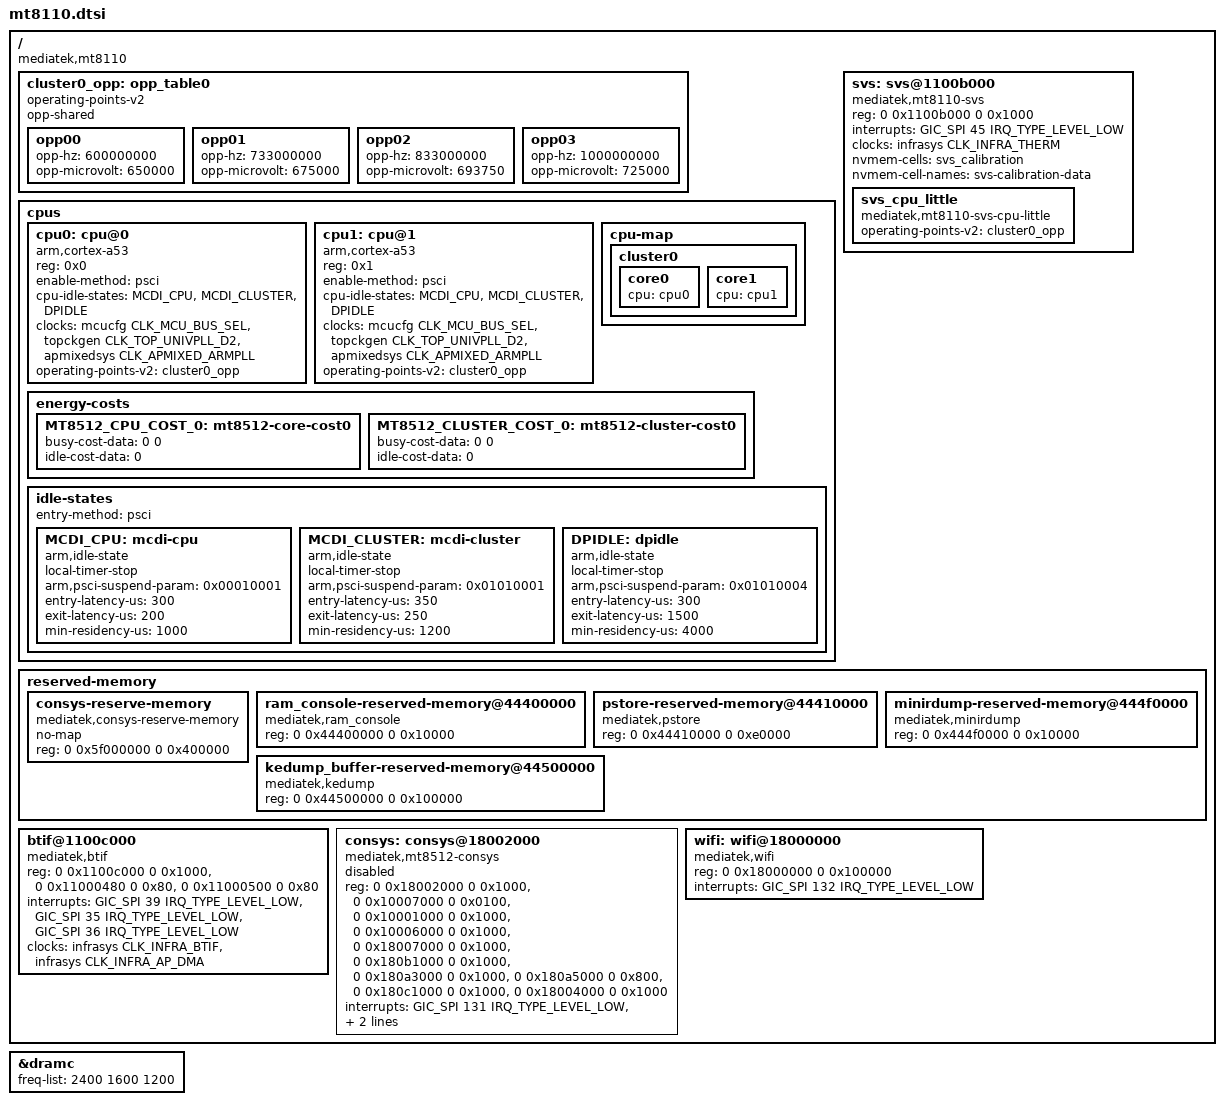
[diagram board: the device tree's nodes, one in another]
/*
 * Copyright (c) 2019 MediaTek Inc.
 *
 * SPDX-License-Identifier: (GPL-2.0 OR MIT)
 */

#include "mt8512.dtsi"

/ {
	compatible = "mediatek,mt8110";
	cluster0_opp: opp_table0 {
		compatible = "operating-points-v2";
		opp-shared;
		opp00 {
			opp-hz = /bits/ 64 <600000000>;
			opp-microvolt = <650000>;
		};
		opp01 {
			opp-hz = /bits/ 64 <733000000>;
			opp-microvolt = <675000>;
		};
		opp02 {
			opp-hz = /bits/ 64 <833000000>;
			opp-microvolt = <693750>;
		};
		opp03 {
			opp-hz = /bits/ 64 <1000000000>;
			opp-microvolt = <725000>;
		};
	};

	cpus {
		#address-cells = <1>;
		#size-cells = <0>;

		cpu0: cpu@0 {
			device_type = "cpu";
			compatible = "arm,cortex-a53";
			reg = <0x0>;
			enable-method = "psci";
			cpu-idle-states = <&MCDI_CPU &MCDI_CLUSTER &DPIDLE>;
			clocks = <&mcucfg CLK_MCU_BUS_SEL>,
				<&topckgen CLK_TOP_UNIVPLL_D2>,
				<&apmixedsys CLK_APMIXED_ARMPLL>;
			clock-names = "cpu", "intermediate", "armpll";
			operating-points-v2 = <&cluster0_opp>;
		};

		cpu1: cpu@1 {
			device_type = "cpu";
			compatible = "arm,cortex-a53";
			reg = <0x1>;
			enable-method = "psci";
			cpu-idle-states = <&MCDI_CPU &MCDI_CLUSTER &DPIDLE>;
			clocks = <&mcucfg CLK_MCU_BUS_SEL>,
				<&topckgen CLK_TOP_UNIVPLL_D2>,
				<&apmixedsys CLK_APMIXED_ARMPLL>;
			clock-names = "cpu", "intermediate", "armpll";
			operating-points-v2 = <&cluster0_opp>;
		};

		cpu-map {
			cluster0 {
				core0 {
					cpu = <&cpu0>;
				};
				core1 {
					cpu = <&cpu1>;
				};
			};
		};

		energy-costs {
			MT8512_CPU_COST_0: mt8512-core-cost0 {
				busy-cost-data = <0 0>;
				idle-cost-data = <0>;
			};
			MT8512_CLUSTER_COST_0: mt8512-cluster-cost0 {
				busy-cost-data = <0 0>;
				idle-cost-data = <0>;
			};
		};

		idle-states {
			entry-method = "psci";

			MCDI_CPU: mcdi-cpu {
				compatible = "arm,idle-state";
				local-timer-stop;
				arm,psci-suspend-param = <0x00010001>;
				entry-latency-us = <300>;
				exit-latency-us = <200>;
				min-residency-us = <1000>;
			};

			MCDI_CLUSTER: mcdi-cluster {
				compatible = "arm,idle-state";
				local-timer-stop;
				arm,psci-suspend-param = <0x01010001>;
				entry-latency-us = <350>;
				exit-latency-us = <250>;
				min-residency-us = <1200>;
			};

			DPIDLE: dpidle {
				compatible = "arm,idle-state";
				local-timer-stop;
				arm,psci-suspend-param = <0x01010004>;
				entry-latency-us = <300>;
				exit-latency-us = <1500>;
				min-residency-us = <4000>;
			};
		};
	};

	svs: svs@1100b000 {
		compatible = "mediatek,mt8110-svs";
		reg = <0 0x1100b000 0 0x1000>;
		interrupts = <GIC_SPI 45 IRQ_TYPE_LEVEL_LOW>;
		clocks = <&infrasys CLK_INFRA_THERM>;
		clock-names = "main_clk";
		nvmem-cells = <&svs_calibration>;
		nvmem-cell-names = "svs-calibration-data";

		svs_cpu_little: svs_cpu_little {
			compatible = "mediatek,mt8110-svs-cpu-little";
			operating-points-v2 = <&cluster0_opp>;
		};
	};

	reserved-memory {
		#address-cells = <2>;
		#size-cells = <2>;
		ranges;

		consys-reserve-memory {
			compatible = "mediatek,consys-reserve-memory";
			no-map;
			reg = <0 0x5f000000 0 0x400000>;
		};

		ram_console-reserved-memory@44400000{
			compatible = "mediatek,ram_console";
			reg = <0 0x44400000 0 0x10000>;
		};

		pstore-reserved-memory@44410000 {
			compatible = "mediatek,pstore";
			reg = <0 0x44410000 0 0xe0000>;
		};

		minirdump-reserved-memory@444f0000{
			compatible = "mediatek,minirdump";
			reg = <0 0x444f0000 0 0x10000>;
		};

		kedump_buffer-reserved-memory@44500000{
			compatible = "mediatek,kedump";
			reg = <0 0x44500000 0 0x100000>;
		};
	};

	btif@1100c000 {
		compatible = "mediatek,btif";
			/*btif base*/
		reg = <0 0x1100c000 0 0x1000>,
			/*btif tx dma base*/
			<0 0x11000480 0 0x80>,
			/*btif rx dma base*/
			<0 0x11000500 0 0x80>;
			/*btif irq, IRQS_Sync ID, btif_irq_b*/
		interrupts = <GIC_SPI 39 IRQ_TYPE_LEVEL_LOW>,
			/*btif tx dma irq*/
			<GIC_SPI 35 IRQ_TYPE_LEVEL_LOW>,
			/*btif rx dma irq*/
			<GIC_SPI 36 IRQ_TYPE_LEVEL_LOW>;
		clocks = <&infrasys CLK_INFRA_BTIF>,
			/*btif clock*/
			<&infrasys CLK_INFRA_AP_DMA>;
			/*ap dma clock*/
		clock-names = "btifc","apdmac";
	};

	consys: consys@18002000 {
		compatible = "mediatek,mt8512-consys";
		#address-cells = <2>;
		#size-cells = <2>;
			/*CONN_MCU_CONFIG_BASE */
		reg = <0 0x18002000 0 0x1000>,
			/*TOP_RGU_BASE */
			<0 0x10007000 0 0x0100>,
			/*INFRACFG_AO_BASE */
			<0 0x10001000 0 0x1000>,
			/*SPM_BASE */
			<0 0x10006000 0 0x1000>,
			/*CONN_HIF_ON_BASE */
			<0 0x18007000 0 0x1000>,
			/*CONN_TOP_MISC_OFF_BASE */
			<0 0x180b1000 0 0x1000>,
			/*CONN_MCU_CFG_ON_BASE */
			<0 0x180a3000 0 0x1000>,
			/*CONN_MCU_CIRQ_BASE */
			<0 0x180a5000 0 0x800>,
			/*CONN_TOP_MISC_ON_BASE */
			<0 0x180c1000 0 0x1000>,
			/*CONN_HIF_PDMA_BASE */
			<0 0x18004000 0 0x1000>;
			/*BGF_EINT */
		interrupts = <GIC_SPI 131 IRQ_TYPE_LEVEL_LOW>,
			/*WDT_EINT */
			   <GIC_SPI 133 IRQ_TYPE_LEVEL_LOW>,
			/*conn2ap_sw_irq*/
			   <GIC_SPI 134 IRQ_TYPE_EDGE_RISING>;
		/*power-domains = <&scpsys MT8512_POWER_DOMAIN_CONN>;*/
		status = "disabled";
	};

	wifi: wifi@18000000 {
		compatible = "mediatek,wifi";
		reg = <0 0x18000000 0 0x100000>;
		interrupts = <GIC_SPI 132 IRQ_TYPE_LEVEL_LOW>;
	};
};

&dramc {
	freq-list = <2400 1600 1200>;
};

/delete-node/ &adsp_mem_reserved;
/delete-node/ &adsp;
